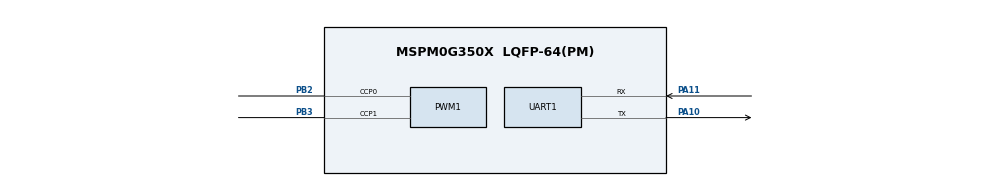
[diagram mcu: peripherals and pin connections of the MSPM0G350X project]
/**
 * @cliArgs --device "MSPM0G350X" --package "LQFP-64(PM)" --part "Default" --product "mspm0_sdk@2.01.00.03"
 * @versions {"tool":"1.20.0+3587"}
 */

/**
 * Import the modules used in this configuration.
 */
const GPIO    = scripting.addModule("/ti/driverlib/GPIO", {}, false);
const GPIO1   = GPIO.addInstance();
const GPIO2   = GPIO.addInstance();
const GPIO3   = GPIO.addInstance();
const GPIO4   = GPIO.addInstance();
const GPIO5   = GPIO.addInstance();
const PWM     = scripting.addModule("/ti/driverlib/PWM", {}, false);
const PWM1    = PWM.addInstance();
const SYSCTL  = scripting.addModule("/ti/driverlib/SYSCTL");
const SYSTICK = scripting.addModule("/ti/driverlib/SYSTICK");
const TIMER   = scripting.addModule("/ti/driverlib/TIMER", {}, false);
const TIMER1  = TIMER.addInstance();
const UART    = scripting.addModule("/ti/driverlib/UART", {}, false);
const UART1   = UART.addInstance();

/**
 * Write custom configuration values to the imported modules.
 */
const divider7       = system.clockTree["PLL_PDIV"];
divider7.divideValue = 2;

const divider9       = system.clockTree["UDIV"];
divider9.divideValue = 2;

const gate7  = system.clockTree["MFCLKGATE"];
gate7.enable = true;

const multiplier2         = system.clockTree["PLL_QDIV"];
multiplier2.multiplyValue = 5;

const mux8       = system.clockTree["HSCLKMUX"];
mux8.inputSelect = "HSCLKMUX_SYSPLL2X";

GPIO1.$name                          = "KEY";
GPIO1.associatedPins.create(2);
GPIO1.associatedPins[0].direction    = "INPUT";
GPIO1.associatedPins[0].$name        = "PIN_2";
GPIO1.associatedPins[1].direction    = "INPUT";
GPIO1.associatedPins[1].$name        = "PIN_3";
GPIO1.associatedPins[1].assignedPort = "PORTB";
GPIO1.associatedPins[1].assignedPin  = "21";

const Board = scripting.addModule("/ti/driverlib/Board", {}, false);

GPIO2.$name                          = "LED";
GPIO2.associatedPins[0].$name        = "PIN_16";
GPIO2.associatedPins[0].assignedPort = "PORTB";
GPIO2.associatedPins[0].assignedPin  = "22";

GPIO3.$name                   = "TB6612";
GPIO3.associatedPins.create(4);
GPIO3.associatedPins[0].$name = "AIN1";
GPIO3.associatedPins[1].$name = "AIN2";
GPIO3.associatedPins[2].$name = "BIN1";
GPIO3.associatedPins[3].$name = "BIN2";

GPIO4.$name                               = "ENCODER";
GPIO4.port                                = "PORTA";
GPIO4.associatedPins.create(4);
GPIO4.associatedPins[0].$name             = "E1A";
GPIO4.associatedPins[0].direction         = "INPUT";
GPIO4.associatedPins[0].interruptEn       = true;
GPIO4.associatedPins[0].interruptPriority = "0";
GPIO4.associatedPins[0].polarity          = "RISE";
GPIO4.associatedPins[1].$name             = "E1B";
GPIO4.associatedPins[1].direction         = "INPUT";
GPIO4.associatedPins[1].interruptEn       = true;
GPIO4.associatedPins[1].interruptPriority = "0";
GPIO4.associatedPins[1].polarity          = "RISE";
GPIO4.associatedPins[2].$name             = "E2A";
GPIO4.associatedPins[2].direction         = "INPUT";
GPIO4.associatedPins[2].interruptEn       = true;
GPIO4.associatedPins[2].interruptPriority = "0";
GPIO4.associatedPins[2].polarity          = "RISE";
GPIO4.associatedPins[3].$name             = "E2B";
GPIO4.associatedPins[3].direction         = "INPUT";
GPIO4.associatedPins[3].interruptEn       = true;
GPIO4.associatedPins[3].polarity          = "RISE";
GPIO4.associatedPins[3].interruptPriority = "0";

GPIO5.$name                              = "sensor";
GPIO5.associatedPins.create(8);
GPIO5.associatedPins[0].direction        = "INPUT";
GPIO5.associatedPins[0].$name            = "L4";
GPIO5.associatedPins[0].internalResistor = "PULL_UP";
GPIO5.associatedPins[1].$name            = "L3";
GPIO5.associatedPins[1].direction        = "INPUT";
GPIO5.associatedPins[1].internalResistor = "PULL_UP";
GPIO5.associatedPins[2].$name            = "L2";
GPIO5.associatedPins[2].internalResistor = "PULL_UP";
GPIO5.associatedPins[2].direction        = "INPUT";
GPIO5.associatedPins[3].$name            = "L1";
GPIO5.associatedPins[3].direction        = "INPUT";
GPIO5.associatedPins[3].internalResistor = "PULL_UP";
GPIO5.associatedPins[4].$name            = "R1";
GPIO5.associatedPins[4].direction        = "INPUT";
GPIO5.associatedPins[4].internalResistor = "PULL_UP";
GPIO5.associatedPins[5].$name            = "R2";
GPIO5.associatedPins[5].direction        = "INPUT";
GPIO5.associatedPins[5].internalResistor = "PULL_UP";
GPIO5.associatedPins[6].$name            = "R3";
GPIO5.associatedPins[6].direction        = "INPUT";
GPIO5.associatedPins[6].internalResistor = "PULL_UP";
GPIO5.associatedPins[7].$name            = "R4";
GPIO5.associatedPins[7].direction        = "INPUT";
GPIO5.associatedPins[7].internalResistor = "PULL_UP";

PWM1.$name                      = "PWM_0";
PWM1.timerStartTimer            = true;
PWM1.pwmMode                    = "EDGE_ALIGN_UP";
PWM1.clockDivider               = 8;
PWM1.clockPrescale              = 4;
PWM1.peripheral.$assign         = "TIMA1";
PWM1.peripheral.ccp0Pin.$assign = "PB2";
PWM1.peripheral.ccp1Pin.$assign = "PB3";
PWM1.PWM_CHANNEL_0.$name        = "ti_driverlib_pwm_PWMTimerCC0";
PWM1.PWM_CHANNEL_1.$name        = "ti_driverlib_pwm_PWMTimerCC1";
PWM1.ccp0PinConfig.$name        = "ti_driverlib_gpio_GPIOPinGeneric4";
PWM1.ccp1PinConfig.$name        = "ti_driverlib_gpio_GPIOPinGeneric5";

SYSCTL.forceDefaultClkConfig = true;
SYSCTL.clockTreeEn           = true;

SYSTICK.periodEnable  = true;
SYSTICK.systickEnable = true;
SYSTICK.period        = 16777216;

TIMER1.$name              = "TIMER_0";
TIMER1.timerMode          = "PERIODIC";
TIMER1.timerStartTimer    = true;
TIMER1.interrupts         = ["ZERO"];
TIMER1.timerPeriod        = "10 ms";
TIMER1.timerClkPrescale   = 100;
TIMER1.peripheral.$assign = "TIMG0";

UART1.$name                    = "UART_0";
UART1.profile                  = "CONFIG_PROFILE_1";
UART1.peripheral.rxPin.$assign = "PA11";
UART1.peripheral.txPin.$assign = "PA10";
UART1.txPinConfig.$name        = "ti_driverlib_gpio_GPIOPinGeneric2";
UART1.rxPinConfig.$name        = "ti_driverlib_gpio_GPIOPinGeneric3";

/**
 * Pinmux solution for unlocked pins/peripherals. This ensures that minor changes to the automatic solver in a future
 * version of the tool will not impact the pinmux you originally saw.  These lines can be completely deleted in order to
 * re-solve from scratch.
 */
GPIO1.associatedPins[0].pin.$suggestSolution = "PB17";
GPIO1.associatedPins[1].pin.$suggestSolution = "PB21";
Board.peripheral.$suggestSolution            = "DEBUGSS";
Board.peripheral.swclkPin.$suggestSolution   = "PA20";
Board.peripheral.swdioPin.$suggestSolution   = "PA19";
GPIO2.associatedPins[0].pin.$suggestSolution = "PB22";
GPIO3.associatedPins[0].pin.$suggestSolution = "PB18";
GPIO3.associatedPins[1].pin.$suggestSolution = "PB19";
GPIO3.associatedPins[2].pin.$suggestSolution = "PA22";
GPIO3.associatedPins[3].pin.$suggestSolution = "PB20";
GPIO4.associatedPins[0].pin.$suggestSolution = "PA21";
GPIO4.associatedPins[1].pin.$suggestSolution = "PA18";
GPIO4.associatedPins[2].pin.$suggestSolution = "PA17";
GPIO4.associatedPins[3].pin.$suggestSolution = "PA16";
GPIO5.associatedPins[0].pin.$suggestSolution = "PA15";
GPIO5.associatedPins[1].pin.$suggestSolution = "PA14";
GPIO5.associatedPins[2].pin.$suggestSolution = "PA13";
GPIO5.associatedPins[3].pin.$suggestSolution = "PA12";
GPIO5.associatedPins[4].pin.$suggestSolution = "PB16";
GPIO5.associatedPins[5].pin.$suggestSolution = "PB15";
GPIO5.associatedPins[6].pin.$suggestSolution = "PB14";
GPIO5.associatedPins[7].pin.$suggestSolution = "PB13";
UART1.peripheral.$suggestSolution            = "UART0";
